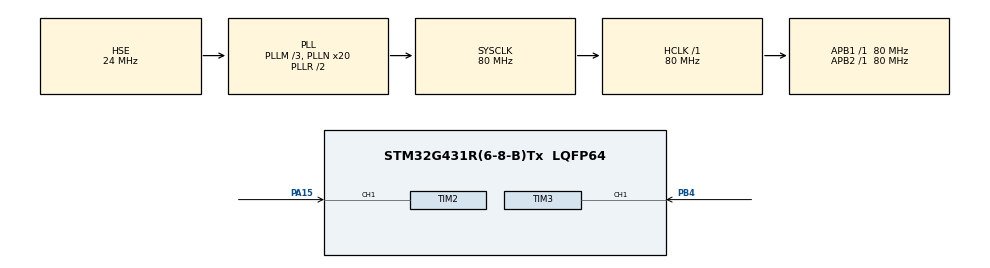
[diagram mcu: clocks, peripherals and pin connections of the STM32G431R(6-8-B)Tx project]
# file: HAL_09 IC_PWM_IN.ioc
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Mcu.Family=STM32G4
Mcu.Name=STM32G431R(6-8-B)Tx
Mcu.Package=LQFP64
NVIC.PriorityGroup=NVIC_PRIORITYGROUP_4
NVIC.TIM2_IRQn=true\:0\:0\:false\:false\:true\:true\:true
NVIC.TIM3_IRQn=true\:0\:0\:false\:false\:true\:true\:true
PA15.Signal=S_TIM2_CH1
PB4.Signal=S_TIM3_CH1
PF0-OSC_IN.Mode=HSE-External-Oscillator
PF0-OSC_IN.Signal=RCC_OSC_IN
PF1-OSC_OUT.Mode=HSE-External-Oscillator
PF1-OSC_OUT.Signal=RCC_OSC_OUT
ProjectManager.HeapSize=0x200
ProjectManager.StackSize=0x400
ProjectManager.TargetToolchain=MDK-ARM V5.27
RCC.ADC12Freq_Value=80000000
RCC.AHBFreq_Value=80000000
RCC.APB1Freq_Value=80000000
RCC.APB1TimFreq_Value=80000000
RCC.APB2Freq_Value=80000000
RCC.APB2TimFreq_Value=80000000
RCC.CortexFreq_Value=80000000
RCC.EXTERNAL_CLOCK_VALUE=12288000
RCC.HCLKFreq_Value=80000000
RCC.HSE_VALUE=24000000
RCC.HSI48_VALUE=48000000
RCC.HSI_VALUE=16000000
RCC.LSE_VALUE=32768
RCC.PLLM=RCC_PLLM_DIV3
RCC.PLLN=20
RCC.PLLSourceVirtual=RCC_PLLSOURCE_HSE
RCC.SYSCLKFreq_VALUE=80000000
RCC.SYSCLKSource=RCC_SYSCLKSOURCE_PLLCLK
RCC.USBFreq_Value=80000000
RCC.VCOOutputFreq_Value=160000000
SH.S_TIM2_CH1.0=TIM2_CH1,PWM_Input_1
SH.S_TIM3_CH1.0=TIM3_CH1,PWM_Input_1
TIM2.AutoReloadPreload=TIM_AUTORELOAD_PRELOAD_ENABLE
TIM2.PeriodNoDither=65535
TIM2.Prescaler=79
TIM3.AutoReloadPreload=TIM_AUTORELOAD_PRELOAD_ENABLE
TIM3.PeriodNoDither=65535
TIM3.Prescaler=79
VP_SYS_VS_DBSignals.Mode=DisableDeadBatterySignals
VP_TIM2_VS_ClockSourceINT.Mode=Internal
VP_TIM3_VS_ClockSourceINT.Mode=Internal
board=custom

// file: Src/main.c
/* USER CODE BEGIN Header */
/**
  ******************************************************************************
  * @file           : main.c
  * @brief          : Main program body
  ******************************************************************************
  * @attention
  *
  * <h2><center>&copy; Copyright (c) 2024 STMicroelectronics.
  * All rights reserved.</center></h2>
  *
  * This software component is licensed by ST under BSD 3-Clause license,
  * the "License"; You may not use this file except in compliance with the
  * License. You may obtain a copy of the License at:
  *                        opensource.org/licenses/BSD-3-Clause
  *
  ******************************************************************************
  */
/* USER CODE END Header */

#include "main.h"
#include "tim.h"
#include "gpio.h"

/* USER CODE BEGIN Includes */
#include "lcd_hal.h"
#include <stdio.h>
/* USER CODE END Includes */

/* USER CODE BEGIN PV */
uint8_t Duty_3;
uint32_t Freq_3;
uint32_t Freq_Value_3;
uint32_t Duty_Value_3;
uint8_t Duty_2;
uint32_t Freq_2;
uint32_t Freq_Value_2;
uint32_t Duty_Value_2;
uint8_t str[30];

/* USER CODE END PV */

void SystemClock_Config(void);

/* USER CODE BEGIN 0 */
void HAL_TIM_IC_CaptureCallback(TIM_HandleTypeDef *htim)//测两个波形的频率和周期
{
  if(htim -> Instance == TIM3)
  {
	  if(htim -> Channel == HAL_TIM_ACTIVE_CHANNEL_1)
	  {
		  Freq_Value_3 = HAL_TIM_ReadCapturedValue(&htim3, TIM_CHANNEL_1);//频率
		  Freq_3 = 1000000 / Freq_Value_3;
	  }
	  else if(htim -> Channel == HAL_TIM_ACTIVE_CHANNEL_2)
	  {
		  Duty_Value_3 = HAL_TIM_ReadCapturedValue(&htim3, TIM_CHANNEL_2);//周期
		  Duty_3 = Duty_Value_3 * 100 / Freq_Value_3;
	  }
  }

   if(htim -> Instance == TIM2)
  {
	  if(htim -> Channel == HAL_TIM_ACTIVE_CHANNEL_1)
	  {
		  Freq_Value_2 = HAL_TIM_ReadCapturedValue(&htim2, TIM_CHANNEL_1);//频率
		  Freq_2 = 1000000 / Freq_Value_2;
	  }
	  else if(htim -> Channel == HAL_TIM_ACTIVE_CHANNEL_2)
	  {
	      Duty_Value_2 = HAL_TIM_ReadCapturedValue(&htim2, TIM_CHANNEL_2);//周期
	      Duty_2 = Duty_Value_2 * 100 / Freq_Value_2;
	  }
  }

}
/* USER CODE END 0 */

int main(void)
{

  /* MCU Configuration--------------------------------------------------------*/

  /* Reset of all peripherals, Initializes the Flash interface and the Systick. */
  HAL_Init();

  /* Configure the system clock */
  SystemClock_Config();

  /* Initialize all configured peripherals */
  MX_GPIO_Init();
  MX_TIM3_Init();
  MX_TIM2_Init();
  /* USER CODE BEGIN 2 */
  LCD_Init();

  HAL_TIM_IC_Start_IT(&htim3, TIM_CHANNEL_1);
  HAL_TIM_IC_Start_IT(&htim3, TIM_CHANNEL_2);

  HAL_TIM_IC_Start_IT(&htim2, TIM_CHANNEL_1);
  HAL_TIM_IC_Start_IT(&htim2, TIM_CHANNEL_2);
  /* USER CODE END 2 */

  /* Infinite loop */
  /* USER CODE BEGIN WHILE */
  while (1)
  {
	sprintf((char *) str, "  Freq(R39):%dhz", Freq_3);
    LCD_DisplayStringLine(Line6, (uint8_t *)str);
	sprintf((char *) str, "  Duty(R39):%d%%", Duty_3);
    LCD_DisplayStringLine(Line7, (uint8_t *)str);
	sprintf((char *) str, "  Freq(R40):%dhz", Freq_2);
    LCD_DisplayStringLine(Line8, (uint8_t *)str);
	sprintf((char *) str, "  Duty(R40):%d%%", Duty_2);
    LCD_DisplayStringLine(Line9, (uint8_t *)str);
	HAL_Delay(200);
    /* USER CODE END WHILE */

  }
}

void SystemClock_Config(void)
{
  RCC_OscInitTypeDef RCC_OscInitStruct = {0};
  RCC_ClkInitTypeDef RCC_ClkInitStruct = {0};

  /** Configure the main internal regulator output voltage
  */
  HAL_PWREx_ControlVoltageScaling(PWR_REGULATOR_VOLTAGE_SCALE1);
  /** Initializes the CPU, AHB and APB busses clocks
  */
  RCC_OscInitStruct.OscillatorType = RCC_OSCILLATORTYPE_HSE;
  RCC_OscInitStruct.HSEState = RCC_HSE_ON;
  RCC_OscInitStruct.PLL.PLLState = RCC_PLL_ON;
  RCC_OscInitStruct.PLL.PLLSource = RCC_PLLSOURCE_HSE;
  RCC_OscInitStruct.PLL.PLLM = RCC_PLLM_DIV3;
  RCC_OscInitStruct.PLL.PLLN = 20;
  RCC_OscInitStruct.PLL.PLLP = RCC_PLLP_DIV2;
  RCC_OscInitStruct.PLL.PLLQ = RCC_PLLQ_DIV2;
  RCC_OscInitStruct.PLL.PLLR = RCC_PLLR_DIV2;
  if (HAL_RCC_OscConfig(&RCC_OscInitStruct) != HAL_OK)
  {
    Error_Handler();
  }
  /** Initializes the CPU, AHB and APB busses clocks
  */
  RCC_ClkInitStruct.ClockType = RCC_CLOCKTYPE_HCLK|RCC_CLOCKTYPE_SYSCLK
                              |RCC_CLOCKTYPE_PCLK1|RCC_CLOCKTYPE_PCLK2;
  RCC_ClkInitStruct.SYSCLKSource = RCC_SYSCLKSOURCE_PLLCLK;
  RCC_ClkInitStruct.AHBCLKDivider = RCC_SYSCLK_DIV1;
  RCC_ClkInitStruct.APB1CLKDivider = RCC_HCLK_DIV1;
  RCC_ClkInitStruct.APB2CLKDivider = RCC_HCLK_DIV1;

  if (HAL_RCC_ClockConfig(&RCC_ClkInitStruct, FLASH_LATENCY_3) != HAL_OK)
  {
    Error_Handler();
  }
}

void Error_Handler(void)
{
}

/************************ (C) COPYRIGHT STMicroelectronics *****END OF FILE****/
